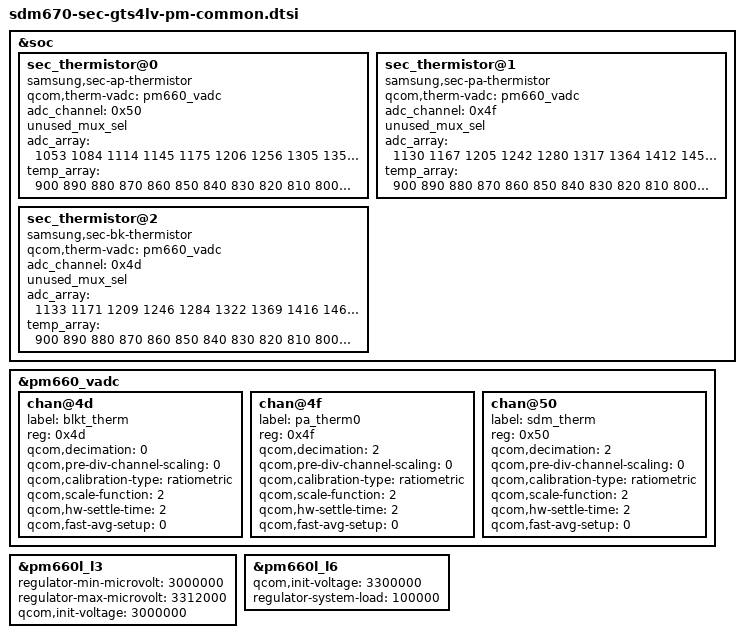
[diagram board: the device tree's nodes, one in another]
/* Copyright (c) 2014, The Linux Foundation. All rights reserved.
 *
 * This program is free software; you can redistribute it and/or modify
 * it under the terms of the GNU General Public License version 2 and
 * only version 2 as published by the Free Software Foundation.
 *
 * This program is distributed in the hope that it will be useful,
 * but WITHOUT ANY WARRANTY; without even the implied warranty of
 * MERCHANTABILITY or FITNESS FOR A PARTICULAR PURPOSE.  See the
 * GNU General Public License for more details.
 */

&soc {
	/* thermistor bringup base on REV 0.1 */
	sec_thermistor@0 {
		compatible = "samsung,sec-ap-thermistor";
		qcom,therm-vadc = <&pm660_vadc>;
		status = "okay";
		adc_channel = <0x50>;
		unused_mux_sel;
		adc_array = <1053 1084 1114 1145 1175 1206 1256 1305 1355 1404
				1454 1508 1563 1617 1672 1726 1787 1848 1909 1970
				2031 2103 2176 2248 2321 2393 2474 2555 2637 2718
				2799 2903 3007 3111 3215 3319 3385 3451 3516 3582
				3648 3827 4006 4186 4365 4544 4693 4843 4992 5142
				5291 5452 5612 5773 5933 6094 6273 6452 6630 6809
				6988 7159 7330 7502 7673 7844 8040 8236 8431 8627
				8823 9014 9206 9397 9589 9780 9969 10157 10346 10534
				10723 10896 11070 11243 11417 11590 11734 11878 12022 12166
				12310
				12511 12711 12912 13112 13313 13430 13547 13663 13780 13897
				13989 14080 14172 14263 14355 14454 14553 14651 14750 14849>;

		temp_array = <900 890 880 870 860 850 840 830 820 810
				800 790 780 770 760 750 740 730 720 710
				700 690 680 670 660 650 640 630 620 610 
				600 590 580 570 560 550 540 530 520 510
				500 490 480 470 460 450 440 430 420 410
				400 390 380 370 360 350 340 330 320 310
				300 290 280 270 260 250 240 230 220 210
				200 190 180 170 160 150 140 130 120 110
				100 90 80 70 60 50 40 30 20 10
				0
				(-10) (-20) (-30) (-40) (-50) (-60) (-70) (-80) (-90) (-100)
				(-110) (-120) (-130) (-140) (-150) (-160) (-170) (-180) (-190) (-200)>;
	};
	
	/* PA Thermistor table */
	sec_thermistor@1 {
		compatible = "samsung,sec-pa-thermistor";
		qcom,therm-vadc = <&pm660_vadc>;
		status = "okay";
		adc_channel = <0x4f>;
		unused_mux_sel;
		adc_array = <1130 1167 1205 1242 1280 1317 1364 1412 1459 1507
				1554 1610 1665 1721 1776 1832 1896 1959 2023 2086
				2150 2229 2308 2388 2467 2546 2633 2720 2806 2893
				2980 3075 3169 3264 3358 3453 3569 3685 3800 3916
				4032 4166 4300 4433 4567 4701 4851 5002 5152 5303
				5453 5628 5803 5977 6152 6327 6501 6675 6848 7022
				7196 7377 7559 7740 7922 8103 8296 8488 8681 8873
				9066 9257 9449 9640 9832 10023 10209 10394 10580 10765
				10951 11122 11292 11463 11633 11804 11960 12116 12273 12429
				12585
				12734 12884 13033 13183 13332 13463 13593 13724 13854 13985
				14081 14178 14274 14371 14467 14564 14661 14758 14855 14952>;

		temp_array = <900 890 880 870 860 850 840 830 820 810
				800 790 780 770 760 750 740 730 720 710
				700 690 680 670 660 650 640 630 620 610 
				600 590 580 570 560 550 540 530 520 510
				500 490 480 470 460 450 440 430 420 410
				400 390 380 370 360 350 340 330 320 310
				300 290 280 270 260 250 240 230 220 210
				200 190 180 170 160 150 140 130 120 110
				100 90 80 70 60 50 40 30 20 10
				0
				(-10) (-20) (-30) (-40) (-50) (-60) (-70) (-80) (-90) (-100)
				(-110) (-120) (-130) (-140) (-150) (-160) (-170) (-180) (-190) (-200)>;
	};

	/* BK Thermistor table */
	sec_thermistor@2 {
		compatible = "samsung,sec-bk-thermistor";
		qcom,therm-vadc = <&pm660_vadc>;
		status = "okay";
		adc_channel = <0x4d>;
		unused_mux_sel;
		adc_array = <1133 1171 1209 1246 1284 1322 1369 1416 1463 1510
				1557 1612 1668 1723 1779 1834 1898 1962 2026 2090
				2154 2235 2315 2396 2476 2557 2642 2727 2811 2896
				2981 3076 3171 3266 3361 3456 3571 3686 3801 3916
				4031 4165 4299 4432 4566 4700 4851 5001 5152 5302
				5453 5625 5797 5969 6141 6313 6484 6655 6825 6996
				7167 7354 7541 7727 7914 8101 8291 8481 8672 8862
				9052 9247 9443 9638 9834 10029 10211 10393 10575 10757
				10939 11116 11293 11471 11648 11825 11990 12154 12319 12483
				12648
				12790 12931 13073 13214 13356 13488 13620 13753 13885 14017
				14114 14211 14307 14404 14501 14598 14694 14791 14887 14984>;

		temp_array = <900 890 880 870 860 850 840 830 820 810
				800 790 780 770 760 750 740 730 720 710
				700 690 680 670 660 650 640 630 620 610 
				600 590 580 570 560 550 540 530 520 510
				500 490 480 470 460 450 440 430 420 410
				400 390 380 370 360 350 340 330 320 310
				300 290 280 270 260 250 240 230 220 210
				200 190 180 170 160 150 140 130 120 110
				100 90 80 70 60 50 40 30 20 10
				0
				(-10) (-20) (-30) (-40) (-50) (-60) (-70) (-80) (-90) (-100)
				(-110) (-120) (-130) (-140) (-150) (-160) (-170) (-180) (-190) (-200)>;
	};
};

&pm660_vadc {
	chan@4d {
		label = "blkt_therm";
		reg = <0x4d>;
		qcom,decimation = <0>;
		qcom,pre-div-channel-scaling = <0>;
		qcom,calibration-type = "ratiometric";
		qcom,scale-function = <2>;
		qcom,hw-settle-time = <2>;
		qcom,fast-avg-setup = <0>;
	};

	chan@4f {
		label = "pa_therm0";
		reg = <0x4f>;
		qcom,decimation = <2>;
		qcom,pre-div-channel-scaling = <0>;
		qcom,calibration-type = "ratiometric";
		qcom,scale-function = <2>;
		qcom,hw-settle-time = <2>;
		qcom,fast-avg-setup = <0>;
	};

	chan@50 {
		label = "sdm_therm";
		reg = <0x50>;
		qcom,decimation = <2>;
		qcom,pre-div-channel-scaling = <0>;
		qcom,calibration-type = "ratiometric";
		qcom,scale-function = <2>;
		qcom,hw-settle-time = <2>;
		qcom,fast-avg-setup = <0>;
	};
};

&pm660l_l3 {
	regulator-min-microvolt = <3000000>;
	regulator-max-microvolt = <3312000>;
	qcom,init-voltage = <3000000>;
};

&pm660l_l6 {
	qcom,init-voltage = <3300000>;
	regulator-system-load = <100000>;
};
